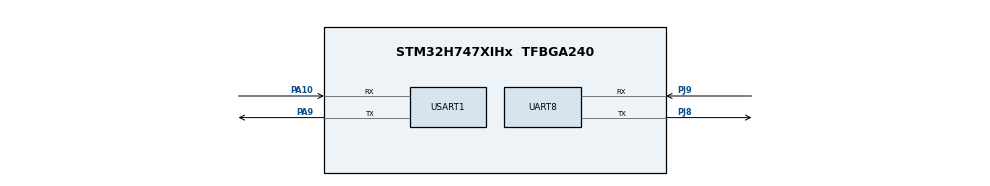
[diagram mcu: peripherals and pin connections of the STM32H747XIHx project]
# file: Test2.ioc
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CortexM4.IPs=BDMA,CORTEX_M4\:I,DEBUG,DMA,FATFS_M4\:I,FREERTOS_M4\:I,IWDG2\:I,MDMA,NVIC2\:I,OPENAMP_M4\:I,PDM2PCM_M4\:I,PWR,RCC,RESMGR_UTILITY,SYS_M4\:I,USB_DEVICE_M4\:I,USB_HOST_M4\:I,VREFBUF,WWDG2\:I
CortexM7.IPs=BDMA\:I,CORTEX_M7\:I,DEBUG\:I,DMA\:I,FATFS_M7\:I,FREERTOS_M7\:I,IWDG1\:I,MDMA\:I,NVIC1\:I,OPENAMP_M7\:I,PDM2PCM_M7\:I,PWR\:I,RCC\:I,RESMGR_UTILITY\:I,SYS\:I,USB_DEVICE_M7\:I,USB_HOST_M7\:I,VREFBUF\:I,WWDG1\:I,UART8\:I,USART1\:I
Mcu.Family=STM32H7
Mcu.Name=STM32H747XIHx
Mcu.Package=TFBGA240
NVIC1.PriorityGroup=NVIC_PRIORITYGROUP_4
NVIC1.UART8_IRQn=true\:0\:0\:false\:false\:true\:true\:true
NVIC1.USART1_IRQn=true\:0\:0\:false\:false\:true\:true\:true
NVIC2.PriorityGroup=NVIC_PRIORITYGROUP_4
PA10.Mode=Asynchronous
PA10.PinAttribute=CortexM7
PA10.Signal=USART1_RX
PA9.Mode=Asynchronous
PA9.PinAttribute=CortexM7
PA9.Signal=USART1_TX
PJ8.Mode=Asynchronous
PJ8.PinAttribute=CortexM7
PJ8.Signal=UART8_TX
PJ9.Mode=Asynchronous
PJ9.PinAttribute=CortexM7
PJ9.Signal=UART8_RX
ProjectManager.HeapSize=0x200
ProjectManager.StackSize=0x400
ProjectManager.TargetToolchain=STM32CubeIDE
RCC.ADCFreq_Value=129000000
RCC.APB1Freq_Value=64000000
RCC.APB2Freq_Value=64000000
RCC.APB3Freq_Value=64000000
RCC.APB4Freq_Value=64000000
RCC.CortexFreq_Value=64000000
RCC.HCLKFreq_Value=64000000
RCC.SYSCLKFreq_VALUE=64000000
RCC.USBFreq_Value=129000000
USART1.VirtualMode-Asynchronous=VM_ASYNC
VP_SYS_M4_VS_Systick.Mode=SysTick
board=custom

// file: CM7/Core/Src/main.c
/* USER CODE BEGIN Header */
/**
  ******************************************************************************
  * @file           : main.c
  * @brief          : Main program body
  ******************************************************************************
  * @attention
  *
  * <h2><center>&copy; Copyright (c) 2020 STMicroelectronics.
  * All rights reserved.</center></h2>
  *
  * This software component is licensed by ST under BSD 3-Clause license,
  * the "License"; You may not use this file except in compliance with the
  * License. You may obtain a copy of the License at:
  *                        opensource.org/licenses/BSD-3-Clause
  *
  ******************************************************************************
  */
/* USER CODE END Header */
#include "main.h"

/* USER CODE BEGIN PD */

#define HSEM_ID_0 (0U) /* HW semaphore 0*/
#define HAL_TIMEOUT_VALUE 0xFFFFFFFF
#define countof(a) (sizeof(a) / sizeof(*(a)))
/* USER CODE END PD */

UART_HandleTypeDef huart8;
UART_HandleTypeDef huart1;
DMA_HandleTypeDef hdma_uart8_rx;

/* USER CODE BEGIN PV */

uint8_t HeaderUART1_TxBuffer[] = "\r\n I'm UART1 TX \r\n";
uint8_t HeaderUART8_TxBuffer[] = "\r\n I'm UART8 TX \r\n";

uint8_t HeaderUART1_RxBuffer[20];
uint8_t HeaderUART8_RxBuffer[20];

/* USER CODE END PV */

void SystemClock_Config(void);
static void MX_GPIO_Init(void);
static void MX_DMA_Init(void);
static void MX_UART8_Init(void);
static void MX_USART1_UART_Init(void);

int main(void)
{
    int32_t timeout;
    /* USER CODE END Boot_Mode_Sequence_0 */

    /* USER CODE BEGIN Boot_Mode_Sequence_1 */
    /* Wait until CPU2 boots and enters in stop mode or timeout*/
    timeout = 0xFFFF;
    while((__HAL_RCC_GET_FLAG(RCC_FLAG_D2CKRDY) != RESET) && (timeout-- > 0));
    if ( timeout < 0 )
    {
     Error_Handler();
    }
    /* USER CODE END Boot_Mode_Sequence_1 */
    /* MCU Configuration--------------------------------------------------------*/

    /* Reset of all peripherals, Initializes the Flash interface and the Systick. */
    HAL_Init();

    /* Configure the system clock */
    SystemClock_Config();
	/* USER CODE BEGIN Boot_Mode_Sequence_2 */
	/* When system initialization is finished, Cortex-M7 will release Cortex-M4 by means of
	HSEM notification */
	/*HW semaphore Clock enable*/
	__HAL_RCC_HSEM_CLK_ENABLE();
	/*Take HSEM */
	HAL_HSEM_FastTake(HSEM_ID_0);
	/*Release HSEM in order to notify the CPU2(CM4)*/
	HAL_HSEM_Release(HSEM_ID_0,0);
	/* wait until CPU2 wakes up from stop mode */
	timeout = 0xFFFF;
	while((__HAL_RCC_GET_FLAG(RCC_FLAG_D2CKRDY) == RESET) && (timeout-- > 0));
	if ( timeout < 0 )
	{
	Error_Handler();
	}
   /* USER CODE END Boot_Mode_Sequence_2 */

   /* Initialize all configured peripherals */
   MX_GPIO_Init();
   //MX_DMA_Init();
   MX_UART8_Init();
   MX_USART1_UART_Init();
   /* Infinite loop */
   /* USER CODE BEGIN WHILE */
   HAL_UART_Transmit(&huart1, (uint8_t*)&HeaderUART1_TxBuffer, countof(HeaderUART1_TxBuffer)-1, HAL_TIMEOUT_VALUE);
   HAL_UART_Transmit(&huart8, (uint8_t*)&HeaderUART8_TxBuffer, countof(HeaderUART8_TxBuffer)-1, HAL_TIMEOUT_VALUE);

//   HAL_UART_Receive(&huart1, (uint8_t*)&HeaderUART1_RxBuffer, 1, HAL_TIMEOUT_VALUE);
//   HAL_UART_Receive(&huart8, (uint8_t*)&HeaderUART8_RxBuffer, 1, HAL_TIMEOUT_VALUE);

   while (1)
   {
     /* USER CODE END WHILE */

   }
}

void HAL_UART_RxCpltCallback(UART_HandleTypeDef *huart){
	if(huart->Instance == huart1.Instance){
		HAL_UART_Transmit(&huart8, (uint8_t*)&HeaderUART1_RxBuffer, countof(HeaderUART1_RxBuffer)-1, HAL_TIMEOUT_VALUE);
		HAL_UART_Receive(&huart1, (uint8_t*)&HeaderUART1_RxBuffer, 1, HAL_TIMEOUT_VALUE);
	}
	if(huart->Instance == huart8.Instance){
		HAL_UART_Transmit(&huart8, (uint8_t*)&HeaderUART8_RxBuffer, countof(HeaderUART8_TxBuffer)-1, HAL_TIMEOUT_VALUE);
		HAL_UART_Receive(&huart8, (uint8_t*)&HeaderUART8_RxBuffer, 1, HAL_TIMEOUT_VALUE);
	}
}
void SystemClock_Config(void)
{
  RCC_OscInitTypeDef RCC_OscInitStruct = {0};
  RCC_ClkInitTypeDef RCC_ClkInitStruct = {0};
  RCC_PeriphCLKInitTypeDef PeriphClkInitStruct = {0};

  /** Supply configuration update enable
  */
  HAL_PWREx_ConfigSupply(PWR_LDO_SUPPLY);
  /** Configure the main internal regulator output voltage
  */
  __HAL_PWR_VOLTAGESCALING_CONFIG(PWR_REGULATOR_VOLTAGE_SCALE3);

  while(!__HAL_PWR_GET_FLAG(PWR_FLAG_VOSRDY)) {}
  /** Initializes the RCC Oscillators according to the specified parameters
  * in the RCC_OscInitTypeDef structure.
  */
  RCC_OscInitStruct.OscillatorType = RCC_OSCILLATORTYPE_HSI;
  RCC_OscInitStruct.HSIState = RCC_HSI_DIV1;
  RCC_OscInitStruct.HSICalibrationValue = RCC_HSICALIBRATION_DEFAULT;
  RCC_OscInitStruct.PLL.PLLState = RCC_PLL_NONE;
  if (HAL_RCC_OscConfig(&RCC_OscInitStruct) != HAL_OK)
  {
    Error_Handler();
  }
  /** Initializes the CPU, AHB and APB buses clocks
  */
  RCC_ClkInitStruct.ClockType = RCC_CLOCKTYPE_HCLK|RCC_CLOCKTYPE_SYSCLK
                              |RCC_CLOCKTYPE_PCLK1|RCC_CLOCKTYPE_PCLK2
                              |RCC_CLOCKTYPE_D3PCLK1|RCC_CLOCKTYPE_D1PCLK1;
  RCC_ClkInitStruct.SYSCLKSource = RCC_SYSCLKSOURCE_HSI;
  RCC_ClkInitStruct.SYSCLKDivider = RCC_SYSCLK_DIV1;
  RCC_ClkInitStruct.AHBCLKDivider = RCC_HCLK_DIV1;
  RCC_ClkInitStruct.APB3CLKDivider = RCC_APB3_DIV1;
  RCC_ClkInitStruct.APB1CLKDivider = RCC_APB1_DIV1;
  RCC_ClkInitStruct.APB2CLKDivider = RCC_APB2_DIV1;
  RCC_ClkInitStruct.APB4CLKDivider = RCC_APB4_DIV1;

  if (HAL_RCC_ClockConfig(&RCC_ClkInitStruct, FLASH_LATENCY_0) != HAL_OK)
  {
    Error_Handler();
  }
  PeriphClkInitStruct.PeriphClockSelection = RCC_PERIPHCLK_USART1|RCC_PERIPHCLK_UART8;
  PeriphClkInitStruct.Usart234578ClockSelection = RCC_USART234578CLKSOURCE_D2PCLK1;
  PeriphClkInitStruct.Usart16ClockSelection = RCC_USART16CLKSOURCE_D2PCLK2;
  if (HAL_RCCEx_PeriphCLKConfig(&PeriphClkInitStruct) != HAL_OK)
  {
    Error_Handler();
  }
}

static void MX_UART8_Init(void)
{

  huart8.Instance = UART8;
  huart8.Init.BaudRate = 115200;
  huart8.Init.WordLength = UART_WORDLENGTH_8B;
  huart8.Init.StopBits = UART_STOPBITS_1;
  huart8.Init.Parity = UART_PARITY_NONE;
  huart8.Init.Mode = UART_MODE_TX_RX;
  huart8.Init.HwFlowCtl = UART_HWCONTROL_NONE;
  huart8.Init.OverSampling = UART_OVERSAMPLING_16;
  huart8.Init.OneBitSampling = UART_ONE_BIT_SAMPLE_DISABLE;
  huart8.Init.ClockPrescaler = UART_PRESCALER_DIV1;
  huart8.AdvancedInit.AdvFeatureInit = UART_ADVFEATURE_NO_INIT;
  if (HAL_UART_Init(&huart8) != HAL_OK)
  {
    Error_Handler();
  }
  if (HAL_UARTEx_SetTxFifoThreshold(&huart8, UART_TXFIFO_THRESHOLD_1_8) != HAL_OK)
  {
    Error_Handler();
  }
  if (HAL_UARTEx_SetRxFifoThreshold(&huart8, UART_RXFIFO_THRESHOLD_1_8) != HAL_OK)
  {
    Error_Handler();
  }
  if (HAL_UARTEx_DisableFifoMode(&huart8) != HAL_OK)
  {
    Error_Handler();
  }

}

static void MX_USART1_UART_Init(void)
{

  huart1.Instance = USART1;
  huart1.Init.BaudRate = 115200;
  huart1.Init.WordLength = UART_WORDLENGTH_8B;
  huart1.Init.StopBits = UART_STOPBITS_1;
  huart1.Init.Parity = UART_PARITY_NONE;
  huart1.Init.Mode = UART_MODE_TX_RX;
  huart1.Init.HwFlowCtl = UART_HWCONTROL_NONE;
  huart1.Init.OverSampling = UART_OVERSAMPLING_16;
  huart1.Init.OneBitSampling = UART_ONE_BIT_SAMPLE_DISABLE;
  huart1.Init.ClockPrescaler = UART_PRESCALER_DIV1;
  huart1.AdvancedInit.AdvFeatureInit = UART_ADVFEATURE_NO_INIT;
  if (HAL_UART_Init(&huart1) != HAL_OK)
  {
    Error_Handler();
  }
  if (HAL_UARTEx_SetTxFifoThreshold(&huart1, UART_TXFIFO_THRESHOLD_1_8) != HAL_OK)
  {
    Error_Handler();
  }
  if (HAL_UARTEx_SetRxFifoThreshold(&huart1, UART_RXFIFO_THRESHOLD_1_8) != HAL_OK)
  {
    Error_Handler();
  }
  if (HAL_UARTEx_DisableFifoMode(&huart1) != HAL_OK)
  {
    Error_Handler();
  }

}

static void MX_DMA_Init(void)
{

  /* DMA controller clock enable */
  __HAL_RCC_DMA1_CLK_ENABLE();

  /* DMA interrupt init */
  /* DMA1_Stream0_IRQn interrupt configuration */
  HAL_NVIC_SetPriority(DMA1_Stream0_IRQn, 0, 0);
  HAL_NVIC_EnableIRQ(DMA1_Stream0_IRQn);

}

static void MX_GPIO_Init(void)
{

  /* GPIO Ports Clock Enable */
  __HAL_RCC_GPIOA_CLK_ENABLE();
  __HAL_RCC_GPIOJ_CLK_ENABLE();

}

void Error_Handler(void)
{
}

/************************ (C) COPYRIGHT STMicroelectronics *****END OF FILE****/
